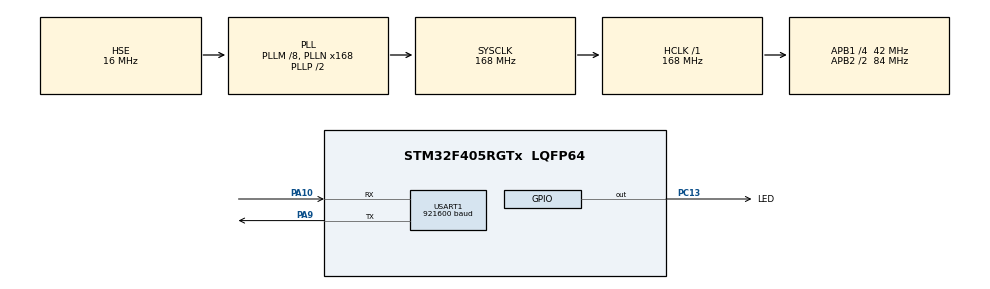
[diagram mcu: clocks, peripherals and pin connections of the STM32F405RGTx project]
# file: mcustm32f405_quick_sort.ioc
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Mcu.Family=STM32F4
Mcu.Name=STM32F405RGTx
Mcu.Package=LQFP64
NVIC.PriorityGroup=NVIC_PRIORITYGROUP_4
PA10.Mode=Asynchronous
PA10.Signal=USART1_RX
PA13.Mode=Trace_Asynchronous_SW
PA13.Signal=SYS_JTMS-SWDIO
PA14.Mode=Trace_Asynchronous_SW
PA14.Signal=SYS_JTCK-SWCLK
PA9.Mode=Asynchronous
PA9.Signal=USART1_TX
PB3.Mode=Trace_Asynchronous_SW
PB3.Signal=SYS_JTDO-SWO
PC13-ANTI_TAMP.GPIO_Label=LED
PC13-ANTI_TAMP.PinState=GPIO_PIN_SET
PC13-ANTI_TAMP.Signal=GPIO_Output
PH0-OSC_IN.Mode=HSE-External-Oscillator
PH0-OSC_IN.Signal=RCC_OSC_IN
PH1-OSC_OUT.Mode=HSE-External-Oscillator
PH1-OSC_OUT.Signal=RCC_OSC_OUT
ProjectManager.HeapSize=0x200
ProjectManager.StackSize=0x400
ProjectManager.TargetToolchain=STM32CubeIDE
RCC.48MHZClocksFreq_Value=48000000
RCC.AHBFreq_Value=168000000
RCC.APB1CLKDivider=RCC_HCLK_DIV4
RCC.APB1Freq_Value=42000000
RCC.APB1TimFreq_Value=84000000
RCC.APB2CLKDivider=RCC_HCLK_DIV2
RCC.APB2Freq_Value=84000000
RCC.APB2TimFreq_Value=168000000
RCC.CortexFreq_Value=168000000
RCC.HCLKFreq_Value=168000000
RCC.HSE_VALUE=16000000
RCC.HSI_VALUE=16000000
RCC.LSE_VALUE=32768
RCC.PLLM=8
RCC.PLLN=168
RCC.PLLQ=7
RCC.PLLSourceVirtual=RCC_PLLSOURCE_HSE
RCC.SYSCLKFreq_VALUE=168000000
RCC.SYSCLKSource=RCC_SYSCLKSOURCE_PLLCLK
RCC.VCOOutputFreq_Value=336000000
TIM2.Prescaler=84 - 1
USART1.BaudRate=921600
USART1.VirtualMode=VM_ASYNC
VP_RNG_VS_RNG.Mode=RNG_Activate
VP_TIM2_VS_ClockSourceINT.Mode=Internal
board=custom

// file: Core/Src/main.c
/* USER CODE BEGIN Header */
/**
 ******************************************************************************
 * @file           : main.c
 * @brief          : Main program body
 ******************************************************************************
 * @attention
 *
 * Copyright (c) 2024 Lars Boegild Thomsen <lth@stm32world.com>
 * All rights reserved.
 *
 * This software is licensed under terms that can be found in the LICENSE file
 * in the root directory of this software component.
 * If no LICENSE file comes with this software, it is provided AS-IS.
 *
 ******************************************************************************
 */
/* USER CODE END Header */
#include "main.h"

/* USER CODE BEGIN Includes */
#include <stdlib.h>
/* USER CODE END Includes */

/* USER CODE BEGIN PD */

#define ARRAY_SIZE 16 * 1024

/* USER CODE END PD */

RNG_HandleTypeDef hrng;

TIM_HandleTypeDef htim2;

UART_HandleTypeDef huart1;

/* USER CODE BEGIN PV */

int arr[ARRAY_SIZE] __attribute__((section(".ccmram")));
//int arr[ARRAY_SIZE];

/* USER CODE END PV */

void SystemClock_Config(void);
static void MX_GPIO_Init(void);
static void MX_RNG_Init(void);
static void MX_USART1_UART_Init(void);
static void MX_TIM2_Init(void);

/* USER CODE BEGIN 0 */

// Send printf to uart1
int _write(int fd, char *ptr, int len) {
    HAL_StatusTypeDef hstatus;

    if (fd == 1 || fd == 2) { // stdout and stderr
        hstatus = HAL_UART_Transmit(&huart1, (uint8_t*) ptr, len, HAL_MAX_DELAY);
        if (hstatus == HAL_OK)
            return len;
        else
            return -1;
    }
    return -1;
}

void fill_random(void *d, uint32_t s) {

    int *int_arr = d;

    for (uint32_t i = 0; i < s / sizeof(int); ++i) {
        int_arr[i] = rand() % 1024;
    }

}

// Function to swap two elements
void swap(int *a, int *b) {
    int temp = *a;
    *a = *b;
    *b = temp;
}

// Partition function
int partition(int arr[], int low, int high) {

    // initialize pivot to be the first element
    int pivot = arr[low];
    int i = low;
    int j = high;

    while (i < j) {

        // condition 1: find the first element greater than
        // the pivot (from starting)
        while (arr[i] <= pivot && i <= high - 1) {
            i++;
        }

        // condition 2: find the first element smaller than
        // the pivot (from last)
        while (arr[j] > pivot && j >= low + 1) {
            j--;
        }
        if (i < j) {
            swap(&arr[i], &arr[j]);
        }
    }
    swap(&arr[low], &arr[j]);
    return j;
}

// QuickSort function
void quickSort(int arr[], int low, int high) {

    //DBG("QS %d - %d\n", low, high);

    if (low < high) {

        // call Partition function to find Partition Index
        int partitionIndex = partition(arr, low, high);

        // Recursively call quickSort() for left and right
        // half based on partition Index
        quickSort(arr, low, partitionIndex - 1);
        quickSort(arr, partitionIndex + 1, high);
    }
}

/* USER CODE END 0 */

int main(void)
{

  /* MCU Configuration--------------------------------------------------------*/

  /* Reset of all peripherals, Initializes the Flash interface and the Systick. */
  HAL_Init();

  /* Configure the system clock */
  SystemClock_Config();

  /* Initialize all configured peripherals */
  MX_GPIO_Init();
  MX_RNG_Init();
  MX_USART1_UART_Init();
  MX_TIM2_Init();
  /* USER CODE BEGIN 2 */

    DBG("Firing up\n");

    HAL_TIM_Base_Start(&htim2);

    int i = 0;
    uint32_t t;

    DBG("Size of int = %d\n", sizeof(i));

    DBG("Filling random\n");

    htim2.Instance->CNT = 0;
    fill_random(arr, sizeof(arr));
    t = htim2.Instance->CNT;
    DBG("fill_random took %lu us\n", t);

//    for (i = 0; i < sizeof(arr) / sizeof(arr[0]); ++i) {
//        DBG("%d\n", arr[i]);
//    }

    DBG("Sorting\n");

    htim2.Instance->CNT = 0;
    quickSort(arr, 0, sizeof(arr) / sizeof(arr[0]) - 1);
    t = htim2.Instance->CNT;
    DBG("quick sort took %lu us\n", t);

//    for (i = 0; i < sizeof(arr) / sizeof(arr[0]); ++i) {
//        DBG("%d\n", arr[i]);
//    }

  /* USER CODE END 2 */

  /* Infinite loop */
  /* USER CODE BEGIN WHILE */

    uint32_t now = 0, last_tick = 0, last_blink = 0;

    while (1)
    {

        now = HAL_GetTick();

        if (now - last_blink >= 500) {
            HAL_GPIO_TogglePin(LED_GPIO_Port, LED_Pin);
            last_blink = now;
        }

//        if (now - last_tick >= 1000) {
//            DBG("Tick %lu\n", now / 1000);
//            last_tick = now;
//        }

    /* USER CODE END WHILE */

    }
}

void SystemClock_Config(void)
{
  RCC_OscInitTypeDef RCC_OscInitStruct = {0};
  RCC_ClkInitTypeDef RCC_ClkInitStruct = {0};

  /** Configure the main internal regulator output voltage
  */
  __HAL_RCC_PWR_CLK_ENABLE();
  __HAL_PWR_VOLTAGESCALING_CONFIG(PWR_REGULATOR_VOLTAGE_SCALE1);

  /** Initializes the RCC Oscillators according to the specified parameters
  * in the RCC_OscInitTypeDef structure.
  */
  RCC_OscInitStruct.OscillatorType = RCC_OSCILLATORTYPE_HSE;
  RCC_OscInitStruct.HSEState = RCC_HSE_ON;
  RCC_OscInitStruct.PLL.PLLState = RCC_PLL_ON;
  RCC_OscInitStruct.PLL.PLLSource = RCC_PLLSOURCE_HSE;
  RCC_OscInitStruct.PLL.PLLM = 8;
  RCC_OscInitStruct.PLL.PLLN = 168;
  RCC_OscInitStruct.PLL.PLLP = RCC_PLLP_DIV2;
  RCC_OscInitStruct.PLL.PLLQ = 7;
  if (HAL_RCC_OscConfig(&RCC_OscInitStruct) != HAL_OK)
  {
    Error_Handler();
  }

  /** Initializes the CPU, AHB and APB buses clocks
  */
  RCC_ClkInitStruct.ClockType = RCC_CLOCKTYPE_HCLK|RCC_CLOCKTYPE_SYSCLK
                              |RCC_CLOCKTYPE_PCLK1|RCC_CLOCKTYPE_PCLK2;
  RCC_ClkInitStruct.SYSCLKSource = RCC_SYSCLKSOURCE_PLLCLK;
  RCC_ClkInitStruct.AHBCLKDivider = RCC_SYSCLK_DIV1;
  RCC_ClkInitStruct.APB1CLKDivider = RCC_HCLK_DIV4;
  RCC_ClkInitStruct.APB2CLKDivider = RCC_HCLK_DIV2;

  if (HAL_RCC_ClockConfig(&RCC_ClkInitStruct, FLASH_LATENCY_5) != HAL_OK)
  {
    Error_Handler();
  }
}

static void MX_RNG_Init(void)
{

  hrng.Instance = RNG;
  if (HAL_RNG_Init(&hrng) != HAL_OK)
  {
    Error_Handler();
  }

}

static void MX_TIM2_Init(void)
{

  TIM_ClockConfigTypeDef sClockSourceConfig = {0};
  TIM_MasterConfigTypeDef sMasterConfig = {0};

  htim2.Instance = TIM2;
  htim2.Init.Prescaler = 84 - 1;
  htim2.Init.CounterMode = TIM_COUNTERMODE_UP;
  htim2.Init.Period = 4294967295;
  htim2.Init.ClockDivision = TIM_CLOCKDIVISION_DIV1;
  htim2.Init.AutoReloadPreload = TIM_AUTORELOAD_PRELOAD_DISABLE;
  if (HAL_TIM_Base_Init(&htim2) != HAL_OK)
  {
    Error_Handler();
  }
  sClockSourceConfig.ClockSource = TIM_CLOCKSOURCE_INTERNAL;
  if (HAL_TIM_ConfigClockSource(&htim2, &sClockSourceConfig) != HAL_OK)
  {
    Error_Handler();
  }
  sMasterConfig.MasterOutputTrigger = TIM_TRGO_RESET;
  sMasterConfig.MasterSlaveMode = TIM_MASTERSLAVEMODE_DISABLE;
  if (HAL_TIMEx_MasterConfigSynchronization(&htim2, &sMasterConfig) != HAL_OK)
  {
    Error_Handler();
  }

}

static void MX_USART1_UART_Init(void)
{

  huart1.Instance = USART1;
  huart1.Init.BaudRate = 921600;
  huart1.Init.WordLength = UART_WORDLENGTH_8B;
  huart1.Init.StopBits = UART_STOPBITS_1;
  huart1.Init.Parity = UART_PARITY_NONE;
  huart1.Init.Mode = UART_MODE_TX_RX;
  huart1.Init.HwFlowCtl = UART_HWCONTROL_NONE;
  huart1.Init.OverSampling = UART_OVERSAMPLING_16;
  if (HAL_UART_Init(&huart1) != HAL_OK)
  {
    Error_Handler();
  }

}

static void MX_GPIO_Init(void)
{
  GPIO_InitTypeDef GPIO_InitStruct = {0};

  /* GPIO Ports Clock Enable */
  __HAL_RCC_GPIOC_CLK_ENABLE();
  __HAL_RCC_GPIOH_CLK_ENABLE();
  __HAL_RCC_GPIOA_CLK_ENABLE();
  __HAL_RCC_GPIOB_CLK_ENABLE();

  /*Configure GPIO pin Output Level */
  HAL_GPIO_WritePin(LED_GPIO_Port, LED_Pin, GPIO_PIN_SET);

  /*Configure GPIO pin : LED_Pin */
  GPIO_InitStruct.Pin = LED_Pin;
  GPIO_InitStruct.Mode = GPIO_MODE_OUTPUT_PP;
  GPIO_InitStruct.Pull = GPIO_NOPULL;
  GPIO_InitStruct.Speed = GPIO_SPEED_FREQ_LOW;
  HAL_GPIO_Init(LED_GPIO_Port, &GPIO_InitStruct);

}

void Error_Handler(void)
{
  /* USER CODE BEGIN Error_Handler_Debug */
    /* User can add his own implementation to report the HAL error return state */
    DBG("Error_Handler\n");
    __disable_irq();
    while (1)
    {
    }
  /* USER CODE END Error_Handler_Debug */
}
